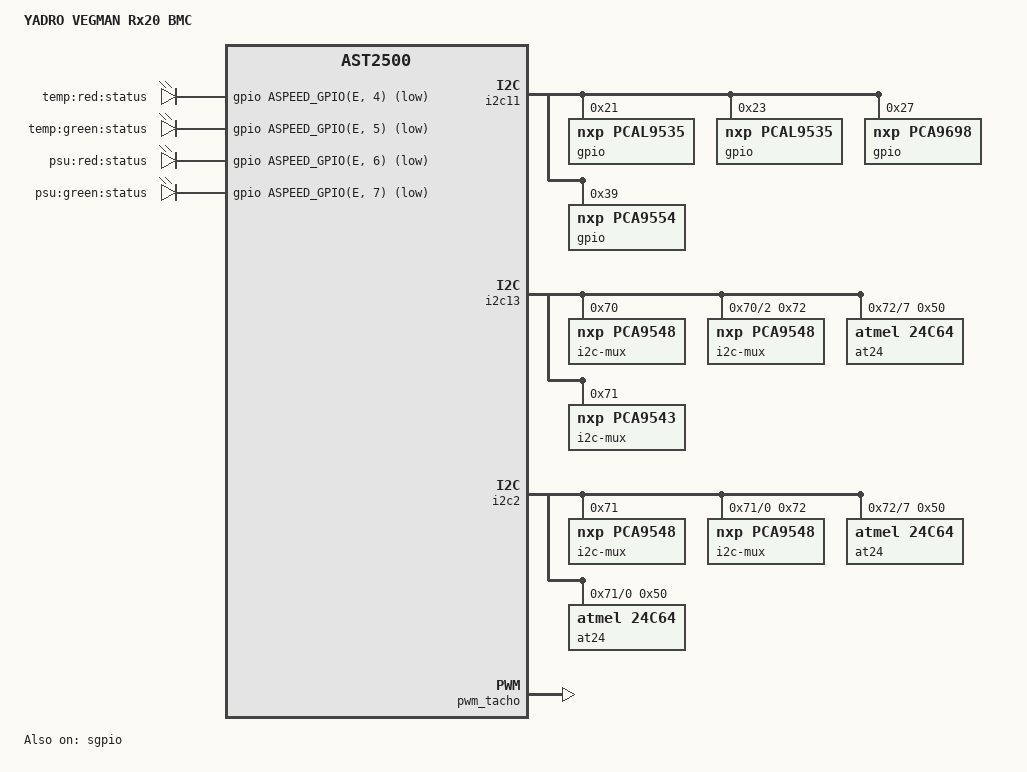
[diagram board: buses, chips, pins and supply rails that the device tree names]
/dts-v1/;
#include "aspeed-bmc-vegman.dtsi"
/ {
	model = "YADRO VEGMAN Rx20 BMC";
	compatible = "yadro,vegman-rx20-bmc", "aspeed,ast2500";
	leds {
		compatible = "gpio-leds";
		temp_alarm {
			label = "temp:red:status";
			default-state = "off";
			gpios = <&gpio ASPEED_GPIO(E, 4) GPIO_ACTIVE_LOW>;
		};
		temp_ok {
			label = "temp:green:status";
			default-state = "off";
			gpios = <&gpio ASPEED_GPIO(E, 5) GPIO_ACTIVE_LOW>;
		};
		psu_fault {
			label = "psu:red:status";
			default-state = "off";
			gpios = <&gpio ASPEED_GPIO(E, 6) GPIO_ACTIVE_LOW>;
		};
		psu_ok {
			label = "psu:green:status";
			default-state = "off";
			gpios = <&gpio ASPEED_GPIO(E, 7) GPIO_ACTIVE_LOW>;
		};
	};
};
&gpio {
	status = "okay";
	gpio-line-names =
	 	"CASE_OPEN_DNP","CASE_OPEN_FAULT_RST_DNP","BEZEL_ON_PWR_P3V3","PWM_PWRGD_EXP_EN","SPEAKER_BMC","FM_FORCE_BMC_UPDATE","","",
	 	"","","","","","","","",
	 	"","","","","","","","",
	 	"","","","","","","","",
	 	"RESET_BUTTON","RESET_OUT","POWER_BUTTON","POWER_OUT","LED_TEMP_STATUS_R","LED_TEMP_STATUS_G","LED_PWR_STATUS_R","LED_PWR_STATUS_G",
	 	"NMI_OUT","CPU1_DISABLE_COD","","","SKT0_FAULT_LED_DNP","SKT1_FAULT_LED_DNP","RST_RGMII_PHYRST_DNP","",
	 	"CPU_ERR2","CPU_CATERR","PCH_BMC_THERMTRIP","SPI_BMC_BOOT_HD","IRQ_NMI_EVENT","SPI_BMC_BOOT_WP","SPI_BMC_BOOT_WP1","",
	 	"PWRGD_P3V3_RISER1","PWRGD_P3V3_RISER2","PWRGD_P3V3_RISER3","","MIO_BIOS_SEL","_SPI_FLASH_HOLD","_SPI_FLASH_WP","FM_240VA_STATUS",
	 	"","","","","","","","",
	 	"","","","","","","","",
	 	"","","","","","","","",
	 	"","","","","","","","",
	 	"SEL_FLASH_SOFT","STATUS_SEL_BMC","","","BMC_WDT_P","ID_BUTTON","PS_PWROK","",
	 	"","","","","","","","",
	 	"","","","","","","","",
	 	"","","","","","","SPI_BIOS_ACTIVE_FLASH_SEL","STATUS_SEL_BIOS",
	 	"","","","","","","","",
	 	"_SPI_BMC_BOOT_CS1","","","","","","","",
	 	"_SPI2_BMC_CS1","RSR_A_SMBEXP_RST_INT","RSR_B_SMBEXP_RST_INT","IRQ_SML0_ALERT_MUX","FP_LED_STATUS_GREEN","FP_LED_STATUS_AMBER","FP_ID_LED","",
	 	"","","","","","","","",
	 	"","","","","","","","",
	 	"","","","","","","","",
	 	"","","","","","","","",
	 	"","","","","","","","",
	 	"SIO_S3","SIO_S5","","SIO_ONCONTROL","","","","",
	 	"FM_BMC_PWR_BTN","SIO_POWER_GOOD","FM_BMC_PWRBTN_OUT","FM_BMC_PCH_SCI_LPC","","","","",
	 	"CPU_CLK_MUX_SEL","IRQ_SML1_PMBUS_ALERT","FM_PVCCIN_CPU0_PWR_IN_ALERT","FM_PVCCIN_CPU1_PWR_IN_ALERT","BMC_SYS_PWR_FAULT","BMC_SYS_PWR_OK","SMI","POST_COMPLETE",
	 	"FM_CPU_BMCINIT","NMI_BUTTON","BMC_WDT_RST1","BMC_WDT_RST2","","","","",
	 	"","","","","","","","";
};
&sgpio {
	ngpios = <80>;
	bus-frequency = <2000000>;
	status = "okay";
	gpio-line-names =
	 	"CPU1_PRESENCE","","CPU1_THERMTRIP","","CPU1_VRHOT","","CPU1_FIVR_FAULT","","CPU1_MEM_ABCD_VRHOT","","CPU1_MEM_EFGH_VRHOT","","","","","",
	 	"CPU1_MISMATCH","","CPU1_MEM_THERM_EVENT","","CPU2_PRESENCE","","CPU2_THERMTRIP","","CPU2_VRHOT","","CPU2_FIVR_FAULT","","CPU2_MEM_ABCD_VRHOT","","CPU2_MEM_EFGH_VRHOT","",
	 	"","","","","CPU2_MISMATCH","","CPU2_MEM_THERM_EVENT","","","","","","","","","",
	 	"","","","","","","","","","","","","","","","",
	 	"","","","","","","","","","","","","","","","",
	 	"SGPIO_PLD_MINOR_REV_BIT0","","SGPIO_PLD_MINOR_REV_BIT1","","SGPIO_PLD_MINOR_REV_BIT2","","SGPIO_PLD_MINOR_REV_BIT3","","SGPIO_PLD_MAJOR_REV_BIT0","","SGPIO_PLD_MAJOR_REV_BIT1","","SGPIO_PLD_MAJOR_REV_BIT2","","SGPIO_PLD_MAJOR_REV_BIT3","",
	 	"MAIN_PLD_MINOR_REV_BIT0","","MAIN_PLD_MINOR_REV_BIT1","","MAIN_PLD_MINOR_REV_BIT2","","MAIN_PLD_MINOR_REV_BIT3","","MAIN_PLD_MAJOR_REV_BIT0","","MAIN_PLD_MAJOR_REV_BIT1","","MAIN_PLD_MAJOR_REV_BIT2","","MAIN_PLD_MAJOR_REV_BIT3","",
	 	"","","","","","","","","","","","","","","","",
	 	"","","","","","","","","","","","","","","","",
	 	"","","","","","","","","","","","","","","","";
};
&i2c11 {
	gpio@21 {
		compatible = "nxp,pcal9535";
		reg = <0x21>;
		gpio-controller;
		#gpio-cells = <2>;
		gpio-line-names =
		 	"ETH3_CLK_REQ", "ETH2_CLK_REQ", "RSR_A_PCIE_X16_2_PRSNT", "RSR_B_PCIE_X16_2_PRSNT", "", "RSR_B_PCIE_X8_3_PRSNT", "RSR_B_PCIE_X8_4_PRSNT", "RSR_B_PCIE_X16_PRSNT_N",
		 	"RSR_B_PCIE_X8_2_PRSNT", "RSR_B_PCIE_X8_1_PRSNT", "NIC_1_PE_BUF_PRSNT", "RSR_A_PCIE_X16_PRSNT", "RSR_A_PCIE_X8_3_PRSNT", "RSR_A_PCIE_X8_2_PRSNT", "RSR_A_PCIE_X8_1_PRSNT_N", "";
	};
	gpio@23 {
		compatible = "nxp,pcal9535";
		reg = <0x23>;
		gpio-controller;
		#gpio-cells = <2>;
		gpio-line-names =
		 	"FM_LINK_WIDTH_ID0", "FM_LINK_WIDTH_ID0", "FM_LINK_WIDTH_ID0", "FM_LINK_WIDTH_ID0", "FM_LINK_WIDTH_ID0", "", "", "",
		 	"", "", "", "", "", "", "", "";
	};
	gpio@27 {
		compatible = "nxp,pca9698";
		reg = <0x27>;
		gpio-controller;
		#gpio-cells = <2>;
		gpio-line-names =
		 	"PWRGD_PS_PWROK", "PWRGD_DSW_PWROK", "PWRGD_P5V_AUX", "PWRGD_P3V3_AUX", "PWRGD_P5V", "PWRGD_P3V3", "PWRGD_P1V8_PCH_AUX", "PWRGD_PCH_PVNN_AUX",
		 	"PWRGD_P1V05_PCH_AUX", "PWRGD_PCH_AUX_VRS", "PWRGD_PVCCIN_CPU0", "PWRGD_PVCCSA_CPU0", "PWRGD_PVCCIO_CPU0", "PWRGD_PVMCP_CPU0", "PWRGD_P1V0_CPU0", "PWRGD_PVDDQ_ABC_CPU0",
		 	"PWRGD_PVPP_ABC_CPU0", "PWRGD_PVTT_ABC_CPU0", "PWRGD_PVDDQ_DEF_CPU0", "PWRGD_PVPP_DEF_CPU0", "PWRGD_PVTT_DEF_CPU0", "PWRGD_PVCCIN_CPU1", "PWRGD_PVCCSA_CPU1", "PWRGD_PVCCIO_CPU1",
		 	"PWRGD_PVMCP_CPU1", "PWRGD_P1V0_CPU1", "PWRGD_PVDDQ_GHJ_CPU1", "PWRGD_PVPP_GHJ_CPU1", "PWRGD_PVTT_GHJ_CPU1", "PWRGD_PVDDQ_KLM_CPU1", "PWRGD_PVPP_KLM_CPU1", "PWRGD_PVTT_KLM_CPU1",
		 	"PCH_PWR_RESET_N", "FM_BOARD_SKU_ID0", "FM_BOARD_SKU_ID1", "FM_BOARD_SKU_ID2", "FM_BOARD_SKU_ID3", "FM_BOARD_SKU_ID4", "FM_BOARD_REV_ID0", "FM_BOARD_REV_ID1";
	};
	gpio@39 {
		compatible = "nxp,pca9554";
		reg = <0x39>;
		gpio-controller;
		#gpio-cells = <2>;
		gpio-line-names =
		 	"FAN_FAULT_0", "FAN_FAULT_1", "FAN_FAULT_2", "FAN_FAULT_3", "FAN_FAULT_4", "FAN_FAULT_5", "FAN_FAULT_6", "";
	};
};
&i2c13 {
	i2c-mux@70 {
		compatible = "nxp,pca9548";
		reg = <0x70>;
		#address-cells = <1>;
		#size-cells = <0>;
		i2c-mux-idle-disconnect;
		i2c@2 {
			#address-cells = <1>;
			#size-cells = <0>;
			reg = <2>;
			i2c-mux@72 {
				compatible = "nxp,pca9548";
				reg = <0x72>;
				#address-cells = <1>;
				#size-cells = <0>;
				i2c@7 {
					#address-cells = <1>;
					#size-cells = <0>;
					reg = <7>;
					at24@50 {
						compatible = "atmel,24c64";
						reg = <0x50>;
						pagesize = <32>;
						size = <8192>;
						address-width = <16>;
					};
				};
			};
		};
	};
	i2c-mux@71 {
		compatible = "nxp,pca9543";
		reg = <0x71>;
		#address-cells = <1>;
		#size-cells = <0>;
		i2c-mux-idle-disconnect;
	};
};
&i2c2 {
	i2c-mux@71 {
		compatible = "nxp,pca9548";
		reg = <0x71>;
		#address-cells = <1>;
		#size-cells = <0>;
		i2c-mux-idle-disconnect;
		i2c@0 {
			#address-cells = <1>;
			#size-cells = <0>;
			reg = <0>;
			i2c-mux@72 {
				compatible = "nxp,pca9548";
				reg = <0x72>;
				#address-cells = <1>;
				#size-cells = <0>;
				i2c@7 {
					#address-cells = <1>;
					#size-cells = <0>;
					reg = <7>;
					at24@50 {
						compatible = "atmel,24c64";
						reg = <0x50>;
						pagesize = <32>;
						size = <8192>;
						address-width = <16>;
					};
				};
			};
			at24@50 {
				compatible = "atmel,24c64";
				reg = <0x50>;
				pagesize = <32>;
				size = <8192>;
				address-width = <16>;
			};
		};
	};
};
&pwm_tacho {
	status = "okay";
	pinctrl-names = "default";
	pinctrl-0 = <&pinctrl_pwm0_default &pinctrl_pwm1_default
			 &pinctrl_pwm2_default &pinctrl_pwm3_default
			 &pinctrl_pwm4_default &pinctrl_pwm5_default
			 &pinctrl_pwm6_default>;
	fan@0 {
		reg = <0x00>;
		aspeed,fan-tach-ch = /bits/ 8 <0x00 0x07>;
	};
	fan@1 {
		reg = <0x01>;
		aspeed,fan-tach-ch = /bits/ 8 <0x01 0x08>;
	};
	fan@2 {
		reg = <0x02>;
		aspeed,fan-tach-ch = /bits/ 8 <0x02 0x09>;
	};
	fan@3 {
		reg = <0x03>;
		aspeed,fan-tach-ch = /bits/ 8 <0x03 0x0A>;
	};
	fan@4 {
		reg = <0x04>;
		aspeed,fan-tach-ch = /bits/ 8 <0x04 0x0B>;
	};
	fan@5 {
		reg = <0x05>;
		aspeed,fan-tach-ch = /bits/ 8 <0x05 0x0C>;
	};
	fan@6 {
		reg = <0x06>;
		aspeed,fan-tach-ch = /bits/ 8 <0x06 0x0D>;
	};
};
